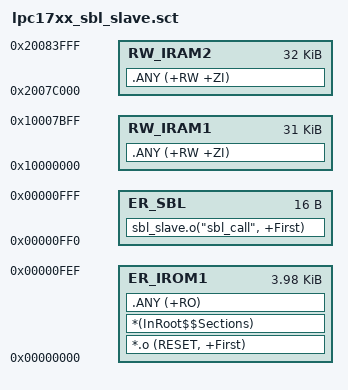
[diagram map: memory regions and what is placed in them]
LR_IROM1 0x00000000 0x00000FF0  {    ; load region size_region
  ER_IROM1 0x00000000 0x00000FF0  {  ; load address = execution address
   *.o (RESET, +First)
   *(InRoot$$Sections)
   .ANY (+RO) 
  }
  RW_IRAM1 0x10000000 0x00007C00  {  ; RW data
   .ANY (+RW +ZI)
  }
  RW_IRAM2 0x2007C000 0x00008000  {
   .ANY (+RW +ZI)
  }
}

LR_SBL_CODE 0x00000FF0 0x00000010{ ; SBL-API
	ER_SBL 0x00000FF0  0x00000010 { ;
      sbl_slave.o("sbl_call", +First)
	}
}








